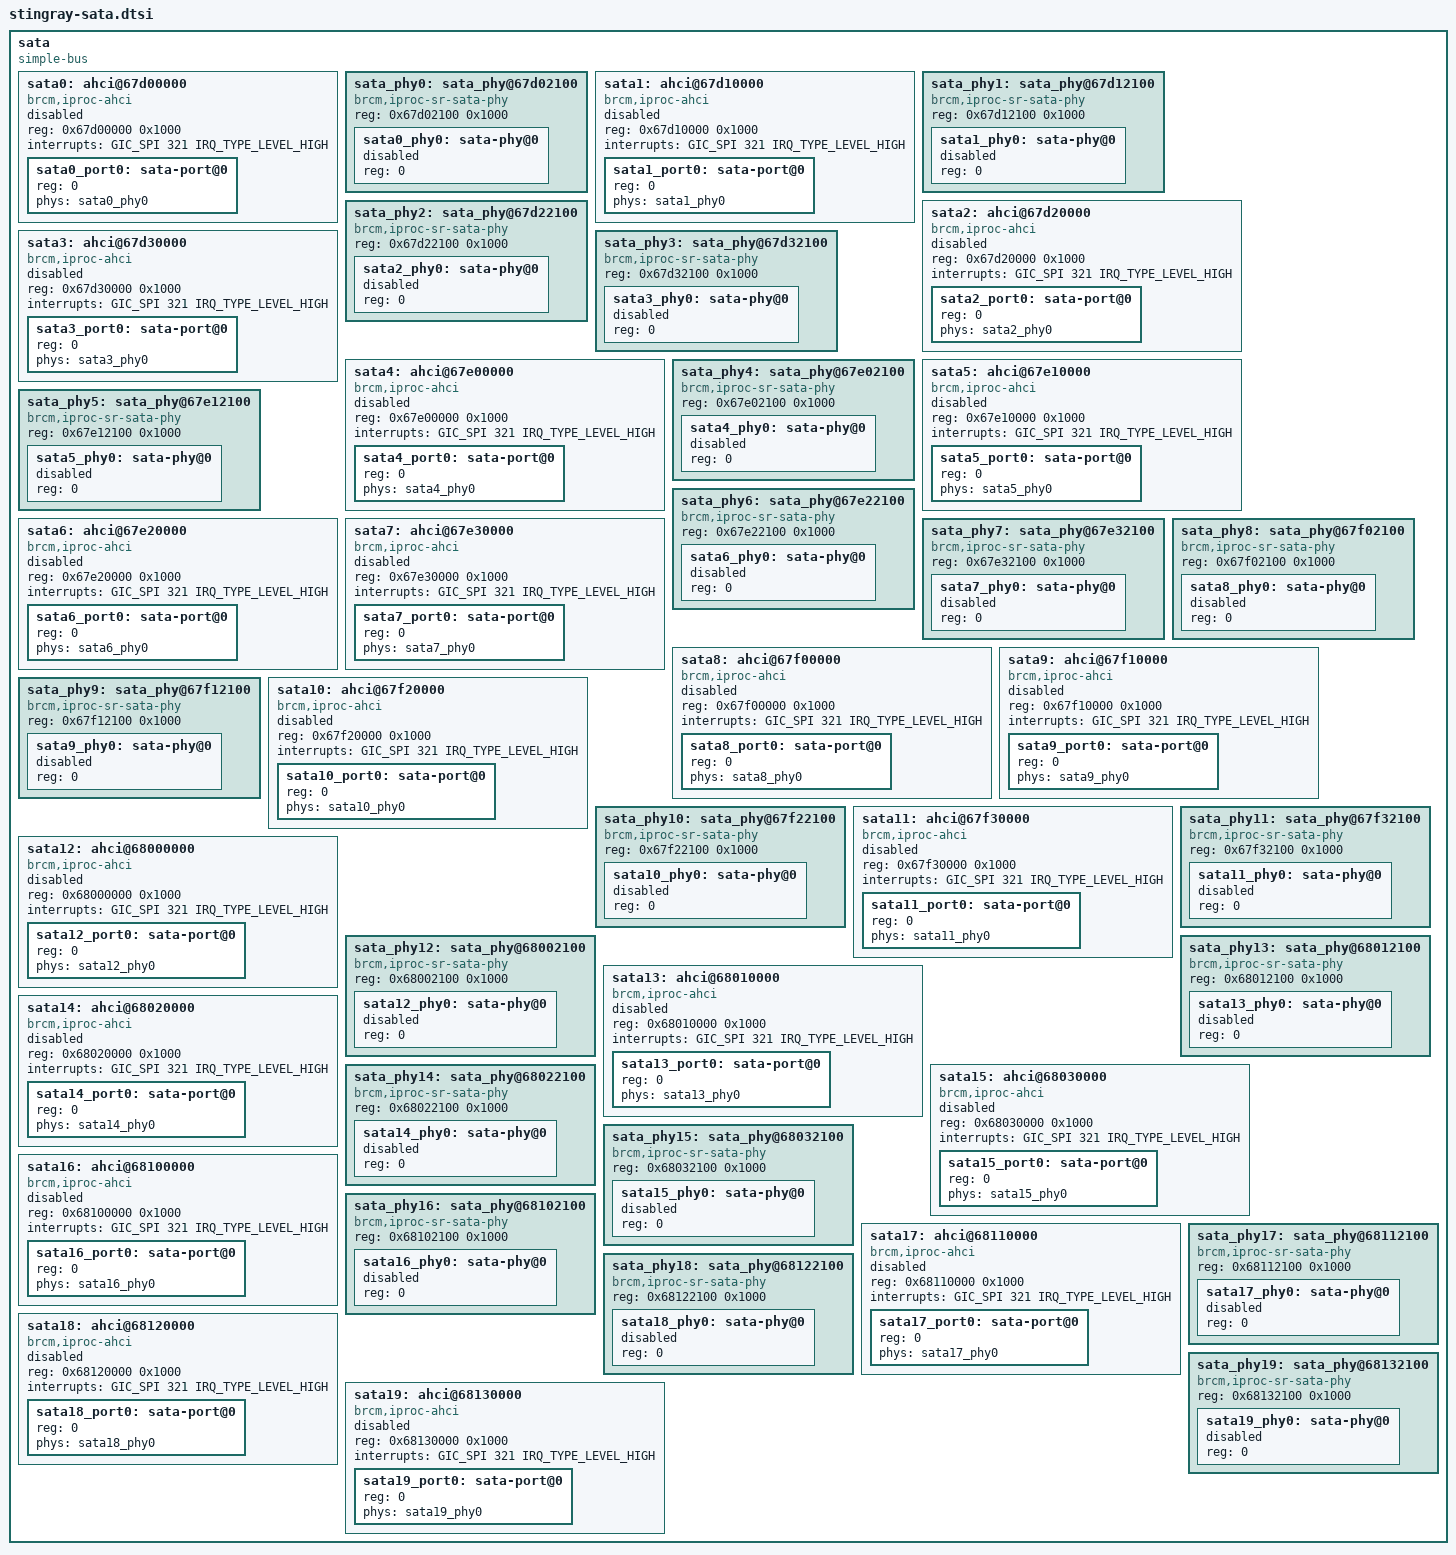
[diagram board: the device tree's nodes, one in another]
/*
 *  BSD LICENSE
 *
 *  Copyright(c) 2016 Broadcom.  All rights reserved.
 *
 *  Redistribution and use in source and binary forms, with or without
 *  modification, are permitted provided that the following conditions
 *  are met:
 *
 *    * Redistributions of source code must retain the above copyright
 *      notice, this list of conditions and the following disclaimer.
 *    * Redistributions in binary form must reproduce the above copyright
 *      notice, this list of conditions and the following disclaimer in
 *      the documentation and/or other materials provided with the
 *      distribution.
 *    * Neither the name of Broadcom Corporation nor the names of its
 *      contributors may be used to endorse or promote products derived
 *      from this software without specific prior written permission.
 *
 *  THIS SOFTWARE IS PROVIDED BY THE COPYRIGHT HOLDERS AND CONTRIBUTORS
 *  "AS IS" AND ANY EXPRESS OR IMPLIED WARRANTIES, INCLUDING, BUT NOT
 *  LIMITED TO, THE IMPLIED WARRANTIES OF MERCHANTABILITY AND FITNESS FOR
 *  A PARTICULAR PURPOSE ARE DISCLAIMED. IN NO EVENT SHALL THE COPYRIGHT
 *  OWNER OR CONTRIBUTORS BE LIABLE FOR ANY DIRECT, INDIRECT, INCIDENTAL,
 *  SPECIAL, EXEMPLARY, OR CONSEQUENTIAL DAMAGES (INCLUDING, BUT NOT
 *  LIMITED TO, PROCUREMENT OF SUBSTITUTE GOODS OR SERVICES; LOSS OF USE,
 *  DATA, OR PROFITS; OR BUSINESS INTERRUPTION) HOWEVER CAUSED AND ON ANY
 *  THEORY OF LIABILITY, WHETHER IN CONTRACT, STRICT LIABILITY, OR TORT
 *  (INCLUDING NEGLIGENCE OR OTHERWISE) ARISING IN ANY WAY OUT OF THE USE
 * OF THIS SOFTWARE, EVEN IF ADVISED OF THE POSSIBILITY OF SUCH DAMAGE.
 */

	sata {
		compatible = "simple-bus";
		#address-cells = <1>;
		#size-cells = <1>;
		ranges = <0 0 0 0xffffffff>;

		sata0: ahci@67d00000 {
			compatible = "brcm,iproc-ahci", "generic-ahci";
			reg = <0x67d00000 0x1000>;
			reg-names = "ahci";
			interrupts = <GIC_SPI 321 IRQ_TYPE_LEVEL_HIGH>;
			#address-cells = <1>;
			#size-cells = <0>;
			status = "disabled";

			sata0_port0: sata-port@0 {
				reg = <0>;
				phys = <&sata0_phy0>;
				phy-names = "sata-phy";
			};
		};

		sata_phy0: sata_phy@67d02100 {
			compatible = "brcm,iproc-sr-sata-phy";
			reg = <0x67d02100 0x1000>;
			reg-names = "phy";
			#address-cells = <1>;
			#size-cells = <0>;

			sata0_phy0: sata-phy@0 {
				reg = <0>;
				#phy-cells = <0>;
				status = "disabled";
			};
		};

		sata1: ahci@67d10000 {
			compatible = "brcm,iproc-ahci", "generic-ahci";
			reg = <0x67d10000 0x1000>;
			reg-names = "ahci";
			interrupts = <GIC_SPI 321 IRQ_TYPE_LEVEL_HIGH>;
			#address-cells = <1>;
			#size-cells = <0>;
			status = "disabled";

			sata1_port0: sata-port@0 {
				reg = <0>;
				phys = <&sata1_phy0>;
				phy-names = "sata-phy";
			};
		};

		sata_phy1: sata_phy@67d12100 {
			compatible = "brcm,iproc-sr-sata-phy";
			reg = <0x67d12100 0x1000>;
			reg-names = "phy";
			#address-cells = <1>;
			#size-cells = <0>;

			sata1_phy0: sata-phy@0 {
				reg = <0>;
				#phy-cells = <0>;
				status = "disabled";
			};
		};

		sata2: ahci@67d20000 {
			compatible = "brcm,iproc-ahci", "generic-ahci";
			reg = <0x67d20000 0x1000>;
			reg-names = "ahci";
			interrupts = <GIC_SPI 321 IRQ_TYPE_LEVEL_HIGH>;
			#address-cells = <1>;
			#size-cells = <0>;
			status = "disabled";

			sata2_port0: sata-port@0 {
				reg = <0>;
				phys = <&sata2_phy0>;
				phy-names = "sata-phy";
			};
		};

		sata_phy2: sata_phy@67d22100 {
			compatible = "brcm,iproc-sr-sata-phy";
			reg = <0x67d22100 0x1000>;
			reg-names = "phy";
			#address-cells = <1>;
			#size-cells = <0>;

			sata2_phy0: sata-phy@0 {
				reg = <0>;
				#phy-cells = <0>;
				status = "disabled";
			};
		};

		sata3: ahci@67d30000 {
			compatible = "brcm,iproc-ahci", "generic-ahci";
			reg = <0x67d30000 0x1000>;
			reg-names = "ahci";
			interrupts = <GIC_SPI 321 IRQ_TYPE_LEVEL_HIGH>;
			#address-cells = <1>;
			#size-cells = <0>;
			status = "disabled";

			sata3_port0: sata-port@0 {
				reg = <0>;
				phys = <&sata3_phy0>;
				phy-names = "sata-phy";
			};
		};

		sata_phy3: sata_phy@67d32100 {
			compatible = "brcm,iproc-sr-sata-phy";
			reg = <0x67d32100 0x1000>;
			reg-names = "phy";
			#address-cells = <1>;
			#size-cells = <0>;

			sata3_phy0: sata-phy@0 {
				reg = <0>;
				#phy-cells = <0>;
				status = "disabled";
			};
		};

		sata4: ahci@67e00000 {
			compatible = "brcm,iproc-ahci", "generic-ahci";
			reg = <0x67e00000 0x1000>;
			reg-names = "ahci";
			interrupts = <GIC_SPI 321 IRQ_TYPE_LEVEL_HIGH>;
			#address-cells = <1>;
			#size-cells = <0>;
			status = "disabled";

			sata4_port0: sata-port@0 {
				reg = <0>;
				phys = <&sata4_phy0>;
				phy-names = "sata-phy";
			};
		};

		sata_phy4: sata_phy@67e02100 {
			compatible = "brcm,iproc-sr-sata-phy";
			reg = <0x67e02100 0x1000>;
			reg-names = "phy";
			#address-cells = <1>;
			#size-cells = <0>;

			sata4_phy0: sata-phy@0 {
				reg = <0>;
				#phy-cells = <0>;
				status = "disabled";
			};
		};

		sata5: ahci@67e10000 {
			compatible = "brcm,iproc-ahci", "generic-ahci";
			reg = <0x67e10000 0x1000>;
			reg-names = "ahci";
			interrupts = <GIC_SPI 321 IRQ_TYPE_LEVEL_HIGH>;
			#address-cells = <1>;
			#size-cells = <0>;
			status = "disabled";

			sata5_port0: sata-port@0 {
				reg = <0>;
				phys = <&sata5_phy0>;
				phy-names = "sata-phy";
			};
		};

		sata_phy5: sata_phy@67e12100 {
			compatible = "brcm,iproc-sr-sata-phy";
			reg = <0x67e12100 0x1000>;
			reg-names = "phy";
			#address-cells = <1>;
			#size-cells = <0>;

			sata5_phy0: sata-phy@0 {
				reg = <0>;
				#phy-cells = <0>;
				status = "disabled";
			};
		};

		sata6: ahci@67e20000 {
			compatible = "brcm,iproc-ahci", "generic-ahci";
			reg = <0x67e20000 0x1000>;
			reg-names = "ahci";
			interrupts = <GIC_SPI 321 IRQ_TYPE_LEVEL_HIGH>;
			#address-cells = <1>;
			#size-cells = <0>;
			status = "disabled";

			sata6_port0: sata-port@0 {
				reg = <0>;
				phys = <&sata6_phy0>;
				phy-names = "sata-phy";
			};
		};

		sata_phy6: sata_phy@67e22100 {
			compatible = "brcm,iproc-sr-sata-phy";
			reg = <0x67e22100 0x1000>;
			reg-names = "phy";
			#address-cells = <1>;
			#size-cells = <0>;

			sata6_phy0: sata-phy@0 {
				reg = <0>;
				#phy-cells = <0>;
				status = "disabled";
			};
		};

		sata7: ahci@67e30000 {
			compatible = "brcm,iproc-ahci", "generic-ahci";
			reg = <0x67e30000 0x1000>;
			reg-names = "ahci";
			interrupts = <GIC_SPI 321 IRQ_TYPE_LEVEL_HIGH>;
			#address-cells = <1>;
			#size-cells = <0>;
			status = "disabled";

			sata7_port0: sata-port@0 {
				reg = <0>;
				phys = <&sata7_phy0>;
				phy-names = "sata-phy";
			};
		};

		sata_phy7: sata_phy@67e32100 {
			compatible = "brcm,iproc-sr-sata-phy";
			reg = <0x67e32100 0x1000>;
			reg-names = "phy";
			#address-cells = <1>;
			#size-cells = <0>;

			sata7_phy0: sata-phy@0 {
				reg = <0>;
				#phy-cells = <0>;
				status = "disabled";
			};
		};

		sata8: ahci@67f00000 {
			compatible = "brcm,iproc-ahci", "generic-ahci";
			reg = <0x67f00000 0x1000>;
			reg-names = "ahci";
			interrupts = <GIC_SPI 321 IRQ_TYPE_LEVEL_HIGH>;
			#address-cells = <1>;
			#size-cells = <0>;
			status = "disabled";

			sata8_port0: sata-port@0 {
				reg = <0>;
				phys = <&sata8_phy0>;
				phy-names = "sata-phy";
			};
		};

		sata_phy8: sata_phy@67f02100 {
			compatible = "brcm,iproc-sr-sata-phy";
			reg = <0x67f02100 0x1000>;
			reg-names = "phy";
			#address-cells = <1>;
			#size-cells = <0>;

			sata8_phy0: sata-phy@0 {
				reg = <0>;
				#phy-cells = <0>;
				status = "disabled";
			};
		};

		sata9: ahci@67f10000 {
			compatible = "brcm,iproc-ahci", "generic-ahci";
			reg = <0x67f10000 0x1000>;
			reg-names = "ahci";
			interrupts = <GIC_SPI 321 IRQ_TYPE_LEVEL_HIGH>;
			#address-cells = <1>;
			#size-cells = <0>;
			status = "disabled";

			sata9_port0: sata-port@0 {
				reg = <0>;
				phys = <&sata9_phy0>;
				phy-names = "sata-phy";
			};
		};

		sata_phy9: sata_phy@67f12100 {
			compatible = "brcm,iproc-sr-sata-phy";
			reg = <0x67f12100 0x1000>;
			reg-names = "phy";
			#address-cells = <1>;
			#size-cells = <0>;

			sata9_phy0: sata-phy@0 {
				reg = <0>;
				#phy-cells = <0>;
				status = "disabled";
			};
		};

		sata10: ahci@67f20000 {
			compatible = "brcm,iproc-ahci", "generic-ahci";
			reg = <0x67f20000 0x1000>;
			reg-names = "ahci";
			interrupts = <GIC_SPI 321 IRQ_TYPE_LEVEL_HIGH>;
			#address-cells = <1>;
			#size-cells = <0>;
			status = "disabled";

			sata10_port0: sata-port@0 {
				reg = <0>;
				phys = <&sata10_phy0>;
				phy-names = "sata-phy";
			};
		};

		sata_phy10: sata_phy@67f22100 {
			compatible = "brcm,iproc-sr-sata-phy";
			reg = <0x67f22100 0x1000>;
			reg-names = "phy";
			#address-cells = <1>;
			#size-cells = <0>;

			sata10_phy0: sata-phy@0 {
				reg = <0>;
				#phy-cells = <0>;
				status = "disabled";
			};
		};

		sata11: ahci@67f30000 {
			compatible = "brcm,iproc-ahci", "generic-ahci";
			reg = <0x67f30000 0x1000>;
			reg-names = "ahci";
			interrupts = <GIC_SPI 321 IRQ_TYPE_LEVEL_HIGH>;
			#address-cells = <1>;
			#size-cells = <0>;
			status = "disabled";

			sata11_port0: sata-port@0 {
				reg = <0>;
				phys = <&sata11_phy0>;
				phy-names = "sata-phy";
			};
		};

		sata_phy11: sata_phy@67f32100 {
			compatible = "brcm,iproc-sr-sata-phy";
			reg = <0x67f32100 0x1000>;
			reg-names = "phy";
			#address-cells = <1>;
			#size-cells = <0>;

			sata11_phy0: sata-phy@0 {
				reg = <0>;
				#phy-cells = <0>;
				status = "disabled";
			};
		};

		sata12: ahci@68000000 {
			compatible = "brcm,iproc-ahci", "generic-ahci";
			reg = <0x68000000 0x1000>;
			reg-names = "ahci";
			interrupts = <GIC_SPI 321 IRQ_TYPE_LEVEL_HIGH>;
			#address-cells = <1>;
			#size-cells = <0>;
			status = "disabled";

			sata12_port0: sata-port@0 {
				reg = <0>;
				phys = <&sata12_phy0>;
				phy-names = "sata-phy";
			};
		};

		sata_phy12: sata_phy@68002100 {
			compatible = "brcm,iproc-sr-sata-phy";
			reg = <0x68002100 0x1000>;
			reg-names = "phy";
			#address-cells = <1>;
			#size-cells = <0>;

			sata12_phy0: sata-phy@0 {
				reg = <0>;
				#phy-cells = <0>;
				status = "disabled";
			};
		};

		sata13: ahci@68010000 {
			compatible = "brcm,iproc-ahci", "generic-ahci";
			reg = <0x68010000 0x1000>;
			reg-names = "ahci";
			interrupts = <GIC_SPI 321 IRQ_TYPE_LEVEL_HIGH>;
			#address-cells = <1>;
			#size-cells = <0>;
			status = "disabled";

			sata13_port0: sata-port@0 {
				reg = <0>;
				phys = <&sata13_phy0>;
				phy-names = "sata-phy";
			};
		};

		sata_phy13: sata_phy@68012100 {
			compatible = "brcm,iproc-sr-sata-phy";
			reg = <0x68012100 0x1000>;
			reg-names = "phy";
			#address-cells = <1>;
			#size-cells = <0>;

			sata13_phy0: sata-phy@0 {
				reg = <0>;
				#phy-cells = <0>;
				status = "disabled";
			};
		};

		sata14: ahci@68020000 {
			compatible = "brcm,iproc-ahci", "generic-ahci";
			reg = <0x68020000 0x1000>;
			reg-names = "ahci";
			interrupts = <GIC_SPI 321 IRQ_TYPE_LEVEL_HIGH>;
			#address-cells = <1>;
			#size-cells = <0>;
			status = "disabled";

			sata14_port0: sata-port@0 {
				reg = <0>;
				phys = <&sata14_phy0>;
				phy-names = "sata-phy";
			};
		};

		sata_phy14: sata_phy@68022100 {
			compatible = "brcm,iproc-sr-sata-phy";
			reg = <0x68022100 0x1000>;
			reg-names = "phy";
			#address-cells = <1>;
			#size-cells = <0>;

			sata14_phy0: sata-phy@0 {
				reg = <0>;
				#phy-cells = <0>;
				status = "disabled";
			};
		};

		sata15: ahci@68030000 {
			compatible = "brcm,iproc-ahci", "generic-ahci";
			reg = <0x68030000 0x1000>;
			reg-names = "ahci";
			interrupts = <GIC_SPI 321 IRQ_TYPE_LEVEL_HIGH>;
			#address-cells = <1>;
			#size-cells = <0>;
			status = "disabled";

			sata15_port0: sata-port@0 {
				reg = <0>;
				phys = <&sata15_phy0>;
				phy-names = "sata-phy";
			};
		};

		sata_phy15: sata_phy@68032100 {
			compatible = "brcm,iproc-sr-sata-phy";
			reg = <0x68032100 0x1000>;
			reg-names = "phy";
			#address-cells = <1>;
			#size-cells = <0>;

			sata15_phy0: sata-phy@0 {
				reg = <0>;
				#phy-cells = <0>;
				status = "disabled";
			};
		};

		sata16: ahci@68100000 {
			compatible = "brcm,iproc-ahci", "generic-ahci";
			reg = <0x68100000 0x1000>;
			reg-names = "ahci";
			interrupts = <GIC_SPI 321 IRQ_TYPE_LEVEL_HIGH>;
			#address-cells = <1>;
			#size-cells = <0>;
			status = "disabled";

			sata16_port0: sata-port@0 {
				reg = <0>;
				phys = <&sata16_phy0>;
				phy-names = "sata-phy";
			};
		};

		sata_phy16: sata_phy@68102100 {
			compatible = "brcm,iproc-sr-sata-phy";
			reg = <0x68102100 0x1000>;
			reg-names = "phy";
			#address-cells = <1>;
			#size-cells = <0>;

			sata16_phy0: sata-phy@0 {
				reg = <0>;
				#phy-cells = <0>;
				status = "disabled";
			};
		};

		sata17: ahci@68110000 {
			compatible = "brcm,iproc-ahci", "generic-ahci";
			reg = <0x68110000 0x1000>;
			reg-names = "ahci";
			interrupts = <GIC_SPI 321 IRQ_TYPE_LEVEL_HIGH>;
			#address-cells = <1>;
			#size-cells = <0>;
			status = "disabled";

			sata17_port0: sata-port@0 {
				reg = <0>;
				phys = <&sata17_phy0>;
				phy-names = "sata-phy";
			};
		};

		sata_phy17: sata_phy@68112100 {
			compatible = "brcm,iproc-sr-sata-phy";
			reg = <0x68112100 0x1000>;
			reg-names = "phy";
			#address-cells = <1>;
			#size-cells = <0>;

			sata17_phy0: sata-phy@0 {
				reg = <0>;
				#phy-cells = <0>;
				status = "disabled";
			};
		};

		sata18: ahci@68120000 {
			compatible = "brcm,iproc-ahci", "generic-ahci";
			reg = <0x68120000 0x1000>;
			reg-names = "ahci";
			interrupts = <GIC_SPI 321 IRQ_TYPE_LEVEL_HIGH>;
			#address-cells = <1>;
			#size-cells = <0>;
			status = "disabled";

			sata18_port0: sata-port@0 {
				reg = <0>;
				phys = <&sata18_phy0>;
				phy-names = "sata-phy";
			};
		};

		sata_phy18: sata_phy@68122100 {
			compatible = "brcm,iproc-sr-sata-phy";
			reg = <0x68122100 0x1000>;
			reg-names = "phy";
			#address-cells = <1>;
			#size-cells = <0>;

			sata18_phy0: sata-phy@0 {
				reg = <0>;
				#phy-cells = <0>;
				status = "disabled";
			};
		};

		sata19: ahci@68130000 {
			compatible = "brcm,iproc-ahci", "generic-ahci";
			reg = <0x68130000 0x1000>;
			reg-names = "ahci";
			interrupts = <GIC_SPI 321 IRQ_TYPE_LEVEL_HIGH>;
			#address-cells = <1>;
			#size-cells = <0>;
			status = "disabled";

			sata19_port0: sata-port@0 {
				reg = <0>;
				phys = <&sata19_phy0>;
				phy-names = "sata-phy";
			};
		};

		sata_phy19: sata_phy@68132100 {
			compatible = "brcm,iproc-sr-sata-phy";
			reg = <0x68132100 0x1000>;
			reg-names = "phy";
			#address-cells = <1>;
			#size-cells = <0>;

			sata19_phy0: sata-phy@0 {
				reg = <0>;
				#phy-cells = <0>;
				status = "disabled";
			};
		};
	};

